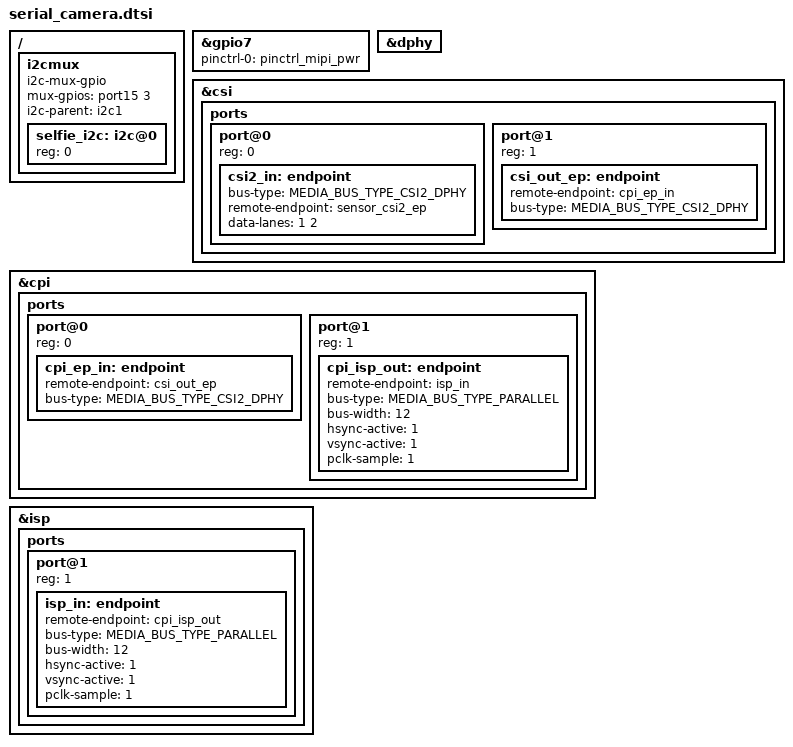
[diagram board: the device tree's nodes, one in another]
// SPDX-License-Identifier: GPL-2.0
/*
 * MIPI CSI-2 (serial) camera graph for Ensemble boards.
 * Mutually exclusive with parallel_camera.dtsi; selected when
 * CPI_PARALLEL is 0.
 *
 * CSI, the ISP output port, and CPI stay here. The selfie sensor is
 * camera/<name>.dtsi, included through ENSEMBLE_CAMERA_SENSOR_DTSI.
 * Yocto sets that path from CAMERA_SENSOR. Every fragment labels its
 * source endpoint sensor_csi2_ep and points it at &csi2_in, so this
 * file does not change when a sensor is added.
 */

/ {
	i2cmux {
		compatible = "i2c-mux-gpio";
		#address-cells = <1>;
		#size-cells = <0>;
		mux-gpios = <&port15 3 GPIO_ACTIVE_HIGH>;
		i2c-parent = <&i2c1>;
		status = "okay";

		selfie_i2c: i2c@0 {
			#address-cells = <1>;
			#size-cells = <0>;
			reg = <0>;
		};
	};
};

#include ENSEMBLE_CAMERA_SENSOR_DTSI

&gpio7 {
	pinctrl-names = "default";
	pinctrl-0 = <&pinctrl_mipi_pwr>;
	status = "okay";
};

&dphy {
	status = CSI_STATUS;
};

&csi {
	status = CSI_STATUS;

	ports {
		#address-cells = <1>;
		#size-cells = <0>;

		port@0 {
			reg = <0>;
			csi2_in: endpoint {
				bus-type = <MEDIA_BUS_TYPE_CSI2_DPHY>;
				remote-endpoint = <&sensor_csi2_ep>;
				data-lanes = <1 2>;
			};
		};

		port@1 {
			reg = <1>;
			csi_out_ep: endpoint {
				remote-endpoint = <&cpi_ep_in>;
				bus-type = <MEDIA_BUS_TYPE_CSI2_DPHY>;
			};
		};
	};
};

&cpi {
	status = CPI_STATUS;

	ports {
		#address-cells = <1>;
		#size-cells = <0>;

		port@0 {
			reg = <0>;
			cpi_ep_in: endpoint {
				remote-endpoint = <&csi_out_ep>;
				bus-type = <MEDIA_BUS_TYPE_CSI2_DPHY>;
			};
		};

		port@1 {
			reg = <1>;
			cpi_isp_out: endpoint {
				remote-endpoint = <&isp_in>;
				bus-type = <MEDIA_BUS_TYPE_PARALLEL>;
				bus-width = <12>;
				hsync-active = <1>;
				vsync-active = <1>;
				pclk-sample = <1>;
			};
		};
	};
};

&isp {
	status = ISP_STATUS;

	ports {
		#address-cells = <1>;
		#size-cells = <0>;

		port@1 {
			reg = <1>;
			isp_in: endpoint {
				remote-endpoint = <&cpi_isp_out>;
				bus-type = <MEDIA_BUS_TYPE_PARALLEL>;
				bus-width = <12>;
				hsync-active = <1>;
				vsync-active = <1>;
				pclk-sample = <1>;
			};
		};
	};
};
